# RP2350 register map
Vendor: Raspberry Pi; Series: RP; File version: 0.1
CPU: CM33 r1p0, little endian, MPU, FPU, DSP, VTOR, 4 interrupt priority bits, 52 interrupts, 8 SAU regions
Registers are 32-bit, read-write, reset 0x0 unless marked. A register's access mark holds for its fields unless they carry their own. Offsets are from the block's base; [hi:lo] are bit positions; {n}, {i} and the like mark numbered series; 'fields as' and 'values as' point back to an identical list; <NAME> marks a mode.

## SIO — Single-cycle IO block Provides core-local and inter-core hardware for the two processors, with single-cycle access.
Base 0xD0000000
Same registers: SIO_NS 0xD0020000
0x00 CPUID reset not defined — Processor core identifier
  [31:0] CPUID ro — Value is 0 when read from processor core 0, and 1 when read from processor core 1.
0x04 GPIO_IN — Input value for GPIO0...31. In the Non-secure SIO, Secure-only GPIOs (as per ACCESSCTRL) appear as zero.
  [31:0] GPIO_IN ro — Pre-defined description
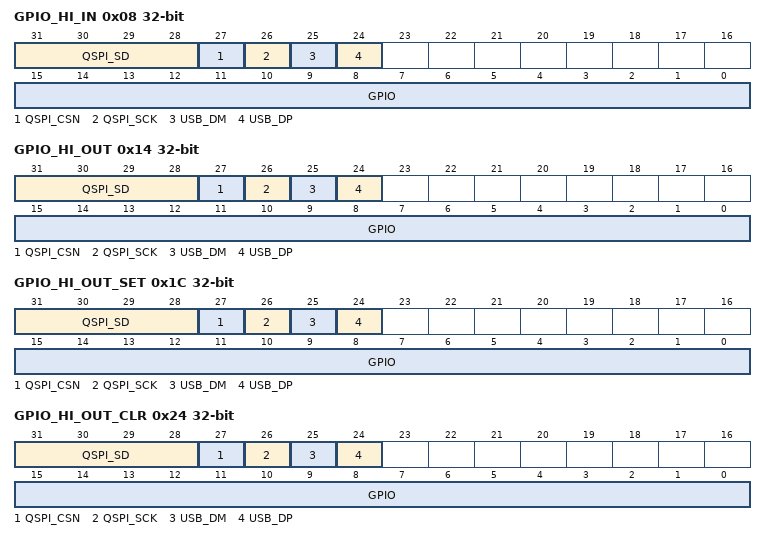
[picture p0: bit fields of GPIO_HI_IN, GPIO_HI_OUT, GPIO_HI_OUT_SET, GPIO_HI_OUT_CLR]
0x08 GPIO_HI_IN — Input value on GPIO32...47, QSPI IOs and USB pins In the Non-secure SIO, Secure-only GPIOs (as per ACCESSCTRL) appear as zero.
  [31:28] QSPI_SD ro — Input value on QSPI SD0 (MOSI), SD1 (MISO), SD2 and SD3 pins
  [27] QSPI_CSN ro — Input value on QSPI CSn pin
  [26] QSPI_SCK ro — Input value on QSPI SCK pin
  [25] USB_DM ro — Input value on USB D- pin
  [24] USB_DP ro — Input value on USB D+ pin
  [15:0] GPIO ro — Input value on GPIO32...47
0x10 GPIO_OUT — GPIO0...31 output value
  [31:0] GPIO_OUT — Set output level (1/0 -> high/low) for GPIO0...31. Reading back gives the last value written, NOT the input value from the pins. If core 0 and core 1 both write to GPIO_OUT simultaneously (or to a SET/CLR/XOR alias), the result is as though the write from core 0 took place first, and the write from core 1 was then applied to that intermediate result. In the Non-secure SIO, Secure-only GPIOs (as per ACCESSCTRL) ignore writes, and their output status reads back as zero. This is also true for SET/CLR/XOR aliases of this register.
0x14 GPIO_HI_OUT — Output value for GPIO32...47, QSPI IOs and USB pins. Write to set output level (1/0 -> high/low). Reading back gives the last value written, NOT the input value from the pins. If core 0 and core 1 both write to GPIO_HI_OUT simultaneously (or to a SET/CLR/XOR alias), the result is as though the write from core 0 took place first, and the write from core 1 was then applied to that intermediate result. In the Non-secure SIO, Secure-only GPIOs (as per ACCESSCTRL) ignore writes, and their output status reads back as zero. This is also true for SET/CLR/XOR aliases of this register.
  [31:28] QSPI_SD — Output value for QSPI SD0 (MOSI), SD1 (MISO), SD2 and SD3 pins
  [27] QSPI_CSN — Output value for QSPI CSn pin
  [26] QSPI_SCK — Output value for QSPI SCK pin
  [25] USB_DM — Output value for USB D- pin
  [24] USB_DP — Output value for USB D+ pin
  [15:0] GPIO — Output value for GPIO32...47
0x18 GPIO_OUT_SET — GPIO0...31 output value set
  [31:0] GPIO_OUT_SET wo — Perform an atomic bit-set on GPIO_OUT, i.e. `GPIO_OUT |= wdata`
0x1C GPIO_HI_OUT_SET — Output value set for GPIO32..47, QSPI IOs and USB pins. Perform an atomic bit-set on GPIO_HI_OUT, i.e. `GPIO_HI_OUT |= wdata`
  [31:28] QSPI_SD wo — Pre-defined description
  [27] QSPI_CSN wo — Pre-defined description
  [26] QSPI_SCK wo — Pre-defined description
  [25] USB_DM wo — Pre-defined description
  [24] USB_DP wo — Pre-defined description
  [15:0] GPIO wo — Pre-defined description
0x20 GPIO_OUT_CLR — GPIO0...31 output value clear
  [31:0] GPIO_OUT_CLR wo — Perform an atomic bit-clear on GPIO_OUT, i.e. `GPIO_OUT &= ~wdata`
0x24 GPIO_HI_OUT_CLR — Output value clear for GPIO32..47, QSPI IOs and USB pins. Perform an atomic bit-clear on GPIO_HI_OUT, i.e. `GPIO_HI_OUT &= ~wdata`
  fields as GPIO_HI_OUT_SET
0x28 GPIO_OUT_XOR — GPIO0...31 output value XOR
  [31:0] GPIO_OUT_XOR wo — Perform an atomic bitwise XOR on GPIO_OUT, i.e. `GPIO_OUT ^= wdata`
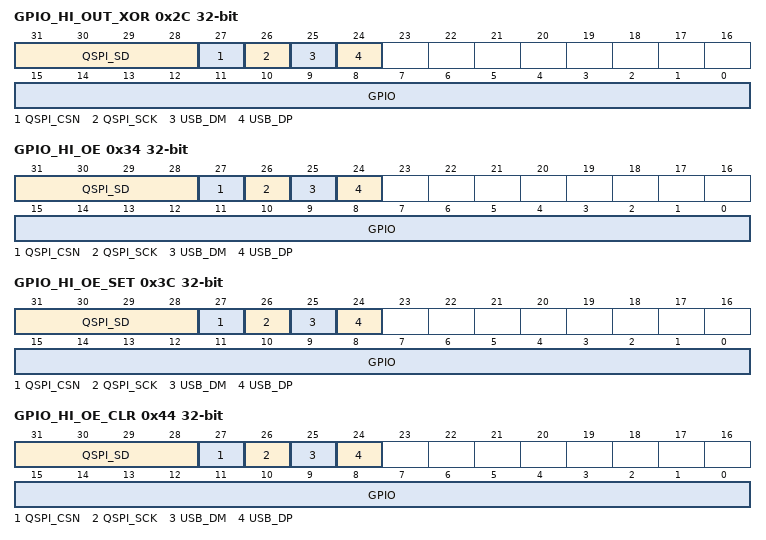
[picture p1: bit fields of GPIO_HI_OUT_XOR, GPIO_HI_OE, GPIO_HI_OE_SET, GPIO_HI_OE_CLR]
0x2C GPIO_HI_OUT_XOR — Output value XOR for GPIO32..47, QSPI IOs and USB pins. Perform an atomic bitwise XOR on GPIO_HI_OUT, i.e. `GPIO_HI_OUT ^= wdata`
  fields as GPIO_HI_OUT_SET
0x30 GPIO_OE — GPIO0...31 output enable
  [31:0] GPIO_OE — Set output enable (1/0 -> output/input) for GPIO0...31. Reading back gives the last value written. If core 0 and core 1 both write to GPIO_OE simultaneously (or to a SET/CLR/XOR alias), the result is as though the write from core 0 took place first, and the write from core 1 was then applied to that intermediate result. In the Non-secure SIO, Secure-only GPIOs (as per ACCESSCTRL) ignore writes, and their output status reads back as zero. This is also true for SET/CLR/XOR aliases of this register.
0x34 GPIO_HI_OE — Output enable value for GPIO32...47, QSPI IOs and USB pins. Write output enable (1/0 -> output/input). Reading back gives the last value written. If core 0 and core 1 both write to GPIO_HI_OE simultaneously (or to a SET/CLR/XOR alias), the result is as though the write from core 0 took place first, and the write from core 1 was then applied to that intermediate result. In the Non-secure SIO, Secure-only GPIOs (as per ACCESSCTRL) ignore writes, and their output status reads back as zero. This is also true for SET/CLR/XOR aliases of this register.
  [31:28] QSPI_SD — Output enable value for QSPI SD0 (MOSI), SD1 (MISO), SD2 and SD3 pins
  [27] QSPI_CSN — Output enable value for QSPI CSn pin
  [26] QSPI_SCK — Output enable value for QSPI SCK pin
  [25] USB_DM — Output enable value for USB D- pin
  [24] USB_DP — Output enable value for USB D+ pin
  [15:0] GPIO — Output enable value for GPIO32...47
0x38 GPIO_OE_SET — GPIO0...31 output enable set
  [31:0] GPIO_OE_SET wo — Perform an atomic bit-set on GPIO_OE, i.e. `GPIO_OE |= wdata`
0x3C GPIO_HI_OE_SET — Output enable set for GPIO32...47, QSPI IOs and USB pins. Perform an atomic bit-set on GPIO_HI_OE, i.e. `GPIO_HI_OE |= wdata`
  fields as GPIO_HI_OUT_SET
0x40 GPIO_OE_CLR — GPIO0...31 output enable clear
  [31:0] GPIO_OE_CLR wo — Perform an atomic bit-clear on GPIO_OE, i.e. `GPIO_OE &= ~wdata`
0x44 GPIO_HI_OE_CLR — Output enable clear for GPIO32...47, QSPI IOs and USB pins. Perform an atomic bit-clear on GPIO_HI_OE, i.e. `GPIO_HI_OE &= ~wdata`
  fields as GPIO_HI_OUT_SET
0x48 GPIO_OE_XOR — GPIO0...31 output enable XOR
  [31:0] GPIO_OE_XOR wo — Perform an atomic bitwise XOR on GPIO_OE, i.e. `GPIO_OE ^= wdata`
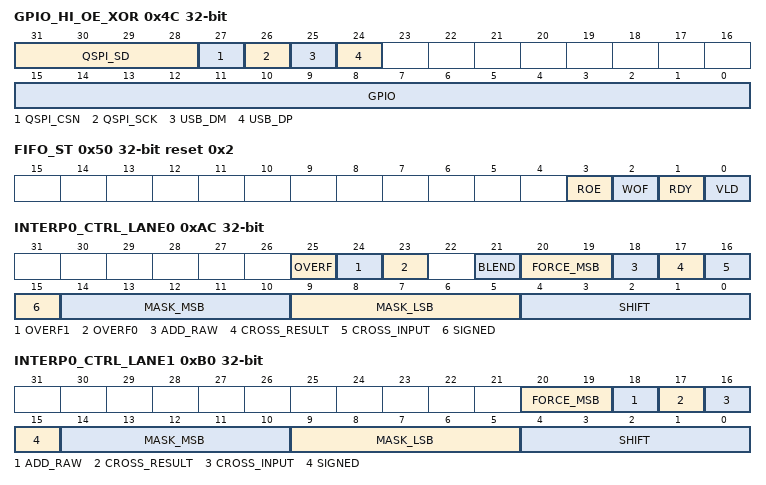
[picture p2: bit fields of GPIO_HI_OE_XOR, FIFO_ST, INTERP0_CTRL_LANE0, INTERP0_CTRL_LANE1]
0x4C GPIO_HI_OE_XOR — Output enable XOR for GPIO32...47, QSPI IOs and USB pins. Perform an atomic bitwise XOR on GPIO_HI_OE, i.e. `GPIO_HI_OE ^= wdata`
  fields as GPIO_HI_OUT_SET
0x50 FIFO_ST reset 0x2 — Status register for inter-core FIFOs (mailboxes). There is one FIFO in the core 0 -> core 1 direction, and one core 1 -> core 0. Both are 32 bits wide and 8 words deep. Core 0 can see the read side of the 1->0 FIFO (RX), and the write side of 0->1 FIFO (TX). Core 1 can see the read side of the 0->1 FIFO (RX), and the write side of 1->0 FIFO (TX). The SIO IRQ for each core is the logical OR of the VLD, WOF and ROE fields of its FIFO_ST register.
  [3] ROE write-1-clears — Sticky flag indicating the RX FIFO was read when empty. This read was ignored by the FIFO.
  [2] WOF write-1-clears — Sticky flag indicating the TX FIFO was written when full. This write was ignored by the FIFO.
  [1] RDY ro — Value is 1 if this core's TX FIFO is not full (i.e. if FIFO_WR is ready for more data)
  [0] VLD ro — Value is 1 if this core's RX FIFO is not empty (i.e. if FIFO_RD is valid)
0x54 FIFO_WR — Write access to this core's TX FIFO
  [31:0] FIFO_WR wo — Pre-defined description
0x58 FIFO_RD reset not defined — Read access to this core's RX FIFO
  [31:0] FIFO_RD ro read-modifies — Pre-defined description
0x5C SPINLOCK_ST — Spinlock state A bitmap containing the state of all 32 spinlocks (1=locked). Mainly intended for debugging.
  [31:0] SPINLOCK_ST ro — Pre-defined description
0x80 INTERP0_ACCUM0 — Read/write access to accumulator 0
  [31:0] INTERP0_ACCUM0 — Pre-defined description
0x84 INTERP0_ACCUM1 — Read/write access to accumulator 1
  [31:0] INTERP0_ACCUM1 — Pre-defined description
{0x88+4i} INTERP0_BASE{i} (i=0..2) — Read/write access to BASE{i} register.
  [31:0] INTERP0_BASE{i} — Pre-defined description
0x94 INTERP0_POP_LANE0 — Read LANE0 result, and simultaneously write lane results to both accumulators (POP).
  [31:0] INTERP0_POP_LANE0 ro — Pre-defined description
0x98 INTERP0_POP_LANE1 — Read LANE1 result, and simultaneously write lane results to both accumulators (POP).
  [31:0] INTERP0_POP_LANE1 ro — Pre-defined description
0x9C INTERP0_POP_FULL — Read FULL result, and simultaneously write lane results to both accumulators (POP).
  [31:0] INTERP0_POP_FULL ro — Pre-defined description
0xA0 INTERP0_PEEK_LANE0 — Read LANE0 result, without altering any internal state (PEEK).
  [31:0] INTERP0_PEEK_LANE0 ro — Pre-defined description
0xA4 INTERP0_PEEK_LANE1 — Read LANE1 result, without altering any internal state (PEEK).
  [31:0] INTERP0_PEEK_LANE1 ro — Pre-defined description
0xA8 INTERP0_PEEK_FULL — Read FULL result, without altering any internal state (PEEK).
  [31:0] INTERP0_PEEK_FULL ro — Pre-defined description
0xAC INTERP0_CTRL_LANE0 — Control register for lane 0
  [25] OVERF ro — Set if either OVERF0 or OVERF1 is set.
  [24] OVERF1 ro — Indicates if any masked-off MSBs in ACCUM1 are set.
  [23] OVERF0 ro — Indicates if any masked-off MSBs in ACCUM0 are set.
  [21] BLEND — Only present on INTERP0 on each core. If BLEND mode is enabled: - LANE1 result is a linear interpolation between BASE0 and BASE1, controlled by the 8 LSBs of lane 1 shift and mask value (a fractional number between 0 and 255/256ths) - LANE0 result does not have BASE0 added (yields only the 8 LSBs of lane 1 shift+mask value) - FULL result does not have lane 1 shift+mask value added (BASE2 + lane 0 shift+mask) LANE1 SIGNED flag controls whether the interpolation is signed or unsigned.
  [20:19] FORCE_MSB — ORed into bits 29:28 of the lane result presented to the processor on the bus. No effect on the internal 32-bit datapath. Handy for using a lane to generate sequence of pointers into flash or SRAM.
  [18] ADD_RAW — If 1, mask + shift is bypassed for LANE0 result. This does not affect FULL result.
  [17] CROSS_RESULT — If 1, feed the opposite lane's result into this lane's accumulator on POP.
  [16] CROSS_INPUT — If 1, feed the opposite lane's accumulator into this lane's shift + mask hardware. Takes effect even if ADD_RAW is set (the CROSS_INPUT mux is before the shift+mask bypass)
  [15] SIGNED — If SIGNED is set, the shifted and masked accumulator value is sign-extended to 32 bits before adding to BASE0, and LANE0 PEEK/POP appear extended to 32 bits when read by processor.
  [14:10] MASK_MSB — The most-significant bit allowed to pass by the mask (inclusive) Setting MSB < LSB may cause chip to turn inside-out
  [9:5] MASK_LSB — The least-significant bit allowed to pass by the mask (inclusive)
  [4:0] SHIFT — Right-rotate applied to accumulator before masking. By appropriately configuring the masks, left and right shifts can be synthesised.
0xB0 INTERP0_CTRL_LANE1 — Control register for lane 1
  [20:19] FORCE_MSB — ORed into bits 29:28 of the lane result presented to the processor on the bus. No effect on the internal 32-bit datapath. Handy for using a lane to generate sequence of pointers into flash or SRAM.
  [18] ADD_RAW — If 1, mask + shift is bypassed for LANE1 result. This does not affect FULL result.
  [17] CROSS_RESULT — If 1, feed the opposite lane's result into this lane's accumulator on POP.
  [16] CROSS_INPUT — If 1, feed the opposite lane's accumulator into this lane's shift + mask hardware. Takes effect even if ADD_RAW is set (the CROSS_INPUT mux is before the shift+mask bypass)
  [15] SIGNED — If SIGNED is set, the shifted and masked accumulator value is sign-extended to 32 bits before adding to BASE1, and LANE1 PEEK/POP appear extended to 32 bits when read by processor.
  [14:10] MASK_MSB — The most-significant bit allowed to pass by the mask (inclusive) Setting MSB < LSB may cause chip to turn inside-out
  [9:5] MASK_LSB — The least-significant bit allowed to pass by the mask (inclusive)
  [4:0] SHIFT — Right-rotate applied to accumulator before masking. By appropriately configuring the masks, left and right shifts can be synthesised.
0xB4 INTERP0_ACCUM0_ADD — Values written here are atomically added to ACCUM0 Reading yields lane 0's raw shift and mask value (BASE0 not added).
  [23:0] INTERP0_ACCUM0_ADD — Pre-defined description
0xB8 INTERP0_ACCUM1_ADD — Values written here are atomically added to ACCUM1 Reading yields lane 1's raw shift and mask value (BASE1 not added).
  [23:0] INTERP0_ACCUM1_ADD — Pre-defined description
0xBC INTERP0_BASE_1AND0 — On write, the lower 16 bits go to BASE0, upper bits to BASE1 simultaneously. Each half is sign-extended to 32 bits if that lane's SIGNED flag is set.
  [31:0] INTERP0_BASE_1AND0 wo — Pre-defined description
0xC0 INTERP1_ACCUM0 — Read/write access to accumulator 0
  [31:0] INTERP1_ACCUM0 — Pre-defined description
0xC4 INTERP1_ACCUM1 — Read/write access to accumulator 1
  [31:0] INTERP1_ACCUM1 — Pre-defined description
{0xC8+4i} INTERP1_BASE{i} (i=0..2) — Read/write access to BASE{i} register.
  [31:0] INTERP1_BASE{i} — Pre-defined description
0xD4 INTERP1_POP_LANE0 — Read LANE0 result, and simultaneously write lane results to both accumulators (POP).
  [31:0] INTERP1_POP_LANE0 ro — Pre-defined description
0xD8 INTERP1_POP_LANE1 — Read LANE1 result, and simultaneously write lane results to both accumulators (POP).
  [31:0] INTERP1_POP_LANE1 ro — Pre-defined description
0xDC INTERP1_POP_FULL — Read FULL result, and simultaneously write lane results to both accumulators (POP).
  [31:0] INTERP1_POP_FULL ro — Pre-defined description
0xE0 INTERP1_PEEK_LANE0 — Read LANE0 result, without altering any internal state (PEEK).
  [31:0] INTERP1_PEEK_LANE0 ro — Pre-defined description
0xE4 INTERP1_PEEK_LANE1 — Read LANE1 result, without altering any internal state (PEEK).
  [31:0] INTERP1_PEEK_LANE1 ro — Pre-defined description
0xE8 INTERP1_PEEK_FULL — Read FULL result, without altering any internal state (PEEK).
  [31:0] INTERP1_PEEK_FULL ro — Pre-defined description
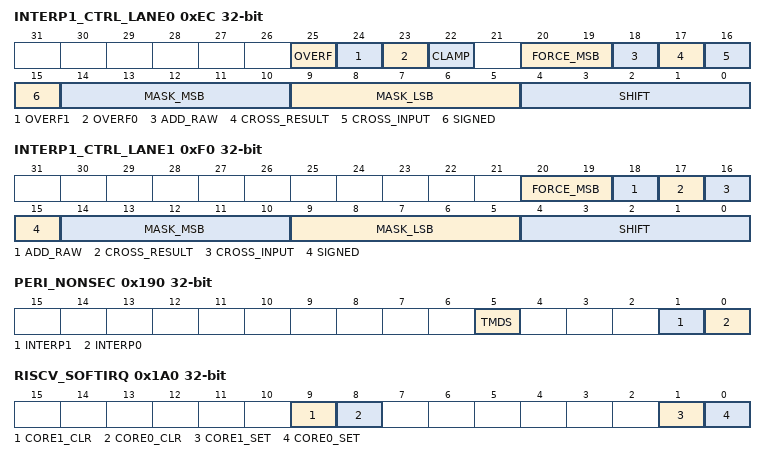
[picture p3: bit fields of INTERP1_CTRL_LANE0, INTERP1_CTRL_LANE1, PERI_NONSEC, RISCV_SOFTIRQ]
0xEC INTERP1_CTRL_LANE0 — Control register for lane 0
  [25] OVERF ro — Set if either OVERF0 or OVERF1 is set.
  [24] OVERF1 ro — Indicates if any masked-off MSBs in ACCUM1 are set.
  [23] OVERF0 ro — Indicates if any masked-off MSBs in ACCUM0 are set.
  [22] CLAMP — Only present on INTERP1 on each core. If CLAMP mode is enabled: - LANE0 result is shifted and masked ACCUM0, clamped by a lower bound of BASE0 and an upper bound of BASE1. - Signedness of these comparisons is determined by LANE0_CTRL_SIGNED
  [20:19] FORCE_MSB — ORed into bits 29:28 of the lane result presented to the processor on the bus. No effect on the internal 32-bit datapath. Handy for using a lane to generate sequence of pointers into flash or SRAM.
  [18] ADD_RAW — If 1, mask + shift is bypassed for LANE0 result. This does not affect FULL result.
  [17] CROSS_RESULT — If 1, feed the opposite lane's result into this lane's accumulator on POP.
  [16] CROSS_INPUT — If 1, feed the opposite lane's accumulator into this lane's shift + mask hardware. Takes effect even if ADD_RAW is set (the CROSS_INPUT mux is before the shift+mask bypass)
  [15] SIGNED — If SIGNED is set, the shifted and masked accumulator value is sign-extended to 32 bits before adding to BASE0, and LANE0 PEEK/POP appear extended to 32 bits when read by processor.
  [14:10] MASK_MSB — The most-significant bit allowed to pass by the mask (inclusive) Setting MSB < LSB may cause chip to turn inside-out
  [9:5] MASK_LSB — The least-significant bit allowed to pass by the mask (inclusive)
  [4:0] SHIFT — Right-rotate applied to accumulator before masking. By appropriately configuring the masks, left and right shifts can be synthesised.
0xF0 INTERP1_CTRL_LANE1 — Control register for lane 1
  fields as INTERP0_CTRL_LANE1
0xF4 INTERP1_ACCUM0_ADD — Values written here are atomically added to ACCUM0 Reading yields lane 0's raw shift and mask value (BASE0 not added).
  [23:0] INTERP1_ACCUM0_ADD — Pre-defined description
0xF8 INTERP1_ACCUM1_ADD — Values written here are atomically added to ACCUM1 Reading yields lane 1's raw shift and mask value (BASE1 not added).
  [23:0] INTERP1_ACCUM1_ADD — Pre-defined description
0xFC INTERP1_BASE_1AND0 — On write, the lower 16 bits go to BASE0, upper bits to BASE1 simultaneously. Each half is sign-extended to 32 bits if that lane's SIGNED flag is set.
  [31:0] INTERP1_BASE_1AND0 wo — Pre-defined description
{0x100+4i} SPINLOCK{i} (i=0..31) — Reading from a spinlock address will: - Return 0 if lock is already locked - Otherwise return nonzero, and simultaneously claim the lock Writing (any value) releases the lock. If core 0 and core 1 attempt to claim the same lock simultaneously, core 0 wins. The value returned on success is 0x1 << lock number.
  [31:0] SPINLOCK{i} read-modifies — Pre-defined description
0x180 DOORBELL_OUT_SET — Trigger a doorbell interrupt on the opposite core. Write 1 to a bit to set the corresponding bit in DOORBELL_IN on the opposite core. This raises the opposite core's doorbell interrupt. Read to get the status of the doorbells currently asserted on the opposite core. This is equivalent to that core reading its own DOORBELL_IN status.
  [7:0] DOORBELL_OUT_SET — Pre-defined description
0x184 DOORBELL_OUT_CLR — Clear doorbells which have been posted to the opposite core. This register is intended for debugging and initialisation purposes. Writing 1 to a bit in DOORBELL_OUT_CLR clears the corresponding bit in DOORBELL_IN on the opposite core. Clearing all bits will cause that core's doorbell interrupt to deassert. Since the usual order of events is for software to send events using DOORBELL_OUT_SET, and acknowledge incoming events by writing to DOORBELL_IN_CLR, this register should be used with caution to avoid race conditions. Reading returns the status of the doorbells currently asserted on the other core, i.e. is equivalent to that core reading its own DOORBELL_IN status.
  [7:0] DOORBELL_OUT_CLR write-1-clears — Pre-defined description
0x188 DOORBELL_IN_SET — Write 1s to trigger doorbell interrupts on this core. Read to get status of doorbells currently asserted on this core.
  [7:0] DOORBELL_IN_SET — Pre-defined description
0x18C DOORBELL_IN_CLR — Check and acknowledge doorbells posted to this core. This core's doorbell interrupt is asserted when any bit in this register is 1. Write 1 to each bit to clear that bit. The doorbell interrupt deasserts once all bits are cleared. Read to get status of doorbells currently asserted on this core.
  [7:0] DOORBELL_IN_CLR write-1-clears — Pre-defined description
0x190 PERI_NONSEC — Detach certain core-local peripherals from Secure SIO, and attach them to Non-secure SIO, so that Non-secure software can use them. Attempting to access one of these peripherals from the Secure SIO when it is attached to the Non-secure SIO, or vice versa, will generate a bus error. This register is per-core, and is only present on the Secure SIO. Most SIO hardware is duplicated across the Secure and Non-secure SIO, so is not listed in this register.
  [5] TMDS — IF 1, detach TMDS encoder (of this core) from the Secure SIO, and attach to the Non-secure SIO.
  [1] INTERP1 — If 1, detach interpolator 1 (of this core) from the Secure SIO, and attach to the Non-secure SIO.
  [0] INTERP0 — If 1, detach interpolator 0 (of this core) from the Secure SIO, and attach to the Non-secure SIO.
0x1A0 RISCV_SOFTIRQ — Control the assertion of the standard software interrupt (MIP.MSIP) on the RISC-V cores. Unlike the RISC-V timer, this interrupt is not routed to a normal system-level interrupt line, so can not be used by the Arm cores. It is safe for both cores to write to this register on the same cycle. The set/clear effect is accumulated across both cores, and then applied. If a flag is both set and cleared on the same cycle, only the set takes effect.
  [9] CORE1_CLR — Write 1 to atomically clear the core 1 software interrupt flag. Read to get the status of this flag.
  [8] CORE0_CLR — Write 1 to atomically clear the core 0 software interrupt flag. Read to get the status of this flag.
  [1] CORE1_SET — Write 1 to atomically set the core 1 software interrupt flag. Read to get the status of this flag.
  [0] CORE0_SET — Write 1 to atomically set the core 0 software interrupt flag. Read to get the status of this flag.
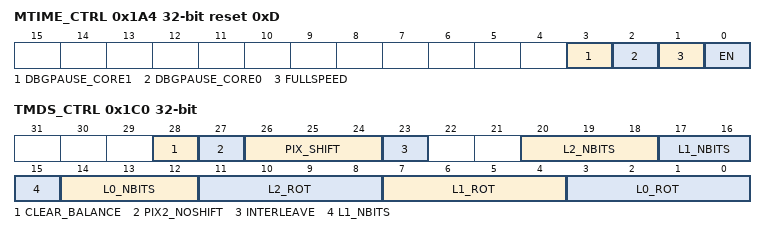
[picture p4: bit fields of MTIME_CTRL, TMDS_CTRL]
0x1A4 MTIME_CTRL reset 0xD — Control register for the RISC-V 64-bit Machine-mode timer. This timer is only present in the Secure SIO, so is only accessible to an Arm core in Secure mode or a RISC-V core in Machine mode. Note whilst this timer follows the RISC-V privileged specification, it is equally usable by the Arm cores. The interrupts are routed to normal system-level interrupt lines as well as to the MIP.MTIP inputs on the RISC-V cores.
  [3] DBGPAUSE_CORE1 — If 1, the timer pauses when core 1 is in the debug halt state.
  [2] DBGPAUSE_CORE0 — If 1, the timer pauses when core 0 is in the debug halt state.
  [1] FULLSPEED — If 1, increment the timer every cycle (i.e. run directly from the system clock), rather than incrementing on the system-level timer tick input.
  [0] EN — Timer enable bit. When 0, the timer will not increment automatically.
0x1B0 MTIME — Read/write access to the high half of RISC-V Machine-mode timer. This register is shared between both cores. If both cores write on the same cycle, core 1 takes precedence.
  [31:0] MTIME — Pre-defined description
0x1B4 MTIMEH — Read/write access to the high half of RISC-V Machine-mode timer. This register is shared between both cores. If both cores write on the same cycle, core 1 takes precedence.
  [31:0] MTIMEH — Pre-defined description
0x1B8 MTIMECMP reset 0xFFFFFFFF — Low half of RISC-V Machine-mode timer comparator. This register is core-local, i.e., each core gets a copy of this register, with the comparison result routed to its own interrupt line. The timer interrupt is asserted whenever MTIME is greater than or equal to MTIMECMP. This comparison is unsigned, and performed on the full 64-bit values.
  [31:0] MTIMECMP — Pre-defined description
0x1BC MTIMECMPH reset 0xFFFFFFFF — High half of RISC-V Machine-mode timer comparator. This register is core-local. The timer interrupt is asserted whenever MTIME is greater than or equal to MTIMECMP. This comparison is unsigned, and performed on the full 64-bit values.
  [31:0] MTIMECMPH — Pre-defined description
0x1C0 TMDS_CTRL — Control register for TMDS encoder.
  [28] CLEAR_BALANCE wo — Clear the running DC balance state of the TMDS encoders. This bit should be written once at the beginning of each scanline.
  [27] PIX2_NOSHIFT — When encoding two pixels's worth of symbols in one cycle (a read of a PEEK/POP_DOUBLE register), the second encoder sees a shifted version of the colour data register. This control disables that shift, so that both encoder layers see the same pixel data. This is used for pixel doubling.
  [26:24] PIX_SHIFT — Shift applied to the colour data register with each read of a POP alias register. Reading from the POP_SINGLE register, or reading from the POP_DOUBLE register with PIX2_NOSHIFT set (for pixel doubling), shifts by the indicated amount. Reading from a POP_DOUBLE register when PIX2_NOSHIFT is clear will shift by double the indicated amount. (Shift by 32 means no shift.)
    0=Do not shift the colour data register; 1=Shift the colour data register by 1 bit; 2=Shift the colour data register by 2 bits; 3=Shift the colour data register by 4 bits; 4=Shift the colour data register by 8 bits; 5=Shift the colour data register by 16 bits
  [23] INTERLEAVE — Enable lane interleaving for reads of PEEK_SINGLE/POP_SINGLE. When interleaving is disabled, each of the 3 symbols appears as a contiguous 10-bit field, with lane 0 being the least-significant and starting at bit 0 of the register. When interleaving is enabled, the symbols are packed into 5 chunks of 3 lanes times 2 bits (30 bits total). Each chunk contains two bits of a TMDS symbol per lane, with lane 0 being the least significant.
  [20:18] L2_NBITS — Number of valid colour MSBs for lane 2 (1-8 bits, encoded as 0 through 7). Remaining LSBs are masked to 0 after the rotate.
  [17:15] L1_NBITS — Number of valid colour MSBs for lane 1 (1-8 bits, encoded as 0 through 7). Remaining LSBs are masked to 0 after the rotate.
  [14:12] L0_NBITS — Number of valid colour MSBs for lane 0 (1-8 bits, encoded as 0 through 7). Remaining LSBs are masked to 0 after the rotate.
  [11:8] L2_ROT — Right-rotate the 16 LSBs of the colour accumulator by 0-15 bits, in order to get the MSB of the lane 2 (red) colour data aligned with the MSB of the 8-bit encoder input. For example, for RGB565 (red most significant), red is bits 15:11, so should be right-rotated by 8 bits to align with bits 7:3 of the encoder input.
  [7:4] L1_ROT — Right-rotate the 16 LSBs of the colour accumulator by 0-15 bits, in order to get the MSB of the lane 1 (green) colour data aligned with the MSB of the 8-bit encoder input. For example, for RGB565, green is bits 10:5, so should be right-rotated by 3 bits to align with bits 7:2 of the encoder input.
  [3:0] L0_ROT — Right-rotate the 16 LSBs of the colour accumulator by 0-15 bits, in order to get the MSB of the lane 0 (blue) colour data aligned with the MSB of the 8-bit encoder input. For example, for RGB565 (red most significant), blue is bits 4:0, so should be right-rotated by 13 to align with bits 7:3 of the encoder input.
0x1C4 TMDS_WDATA — Write-only access to the TMDS colour data register.
  [31:0] TMDS_WDATA wo — Pre-defined description
0x1C8 TMDS_PEEK_SINGLE — Get the encoding of one pixel's worth of colour data, packed into a 32-bit value (3x10-bit symbols). The PEEK alias does not shift the colour register when read, but still advances the running DC balance state of each encoder. This is useful for pixel doubling.
  [31:0] TMDS_PEEK_SINGLE ro read-modifies — Pre-defined description
0x1CC TMDS_POP_SINGLE — Get the encoding of one pixel's worth of colour data, packed into a 32-bit value. The packing is 5 chunks of 3 lanes times 2 bits (30 bits total). Each chunk contains two bits of a TMDS symbol per lane. This format is intended for shifting out with the HSTX peripheral on RP2350. The POP alias shifts the colour register when read, as well as advancing the running DC balance state of each encoder.
  [31:0] TMDS_POP_SINGLE ro read-modifies — Pre-defined description
{0x1D0+8i} TMDS_PEEK_DOUBLE_L{i} (i=0..2) — Get lane {i} of the encoding of two pixels' worth of colour data. Two 10-bit TMDS symbols are packed at the bottom of a 32-bit word. The PEEK alias does not shift the colour register when read, but still advances the lane {i} DC balance state. This is useful if all 3 lanes' worth of encode are to be read at once, rather than processing the entire scanline for one lane before moving to the next lane.
  [31:0] TMDS_PEEK_DOUBLE_L{i} ro read-modifies — Pre-defined description
{0x1D4+8i} TMDS_POP_DOUBLE_L{i} (i=0..2) — Get lane {i} of the encoding of two pixels' worth of colour data. Two 10-bit TMDS symbols are packed at the bottom of a 32-bit word. The POP alias shifts the colour register when read, according to the values of PIX_SHIFT and PIX2_NOSHIFT.
  [31:0] TMDS_POP_DOUBLE_L{i} ro read-modifies — Pre-defined description
